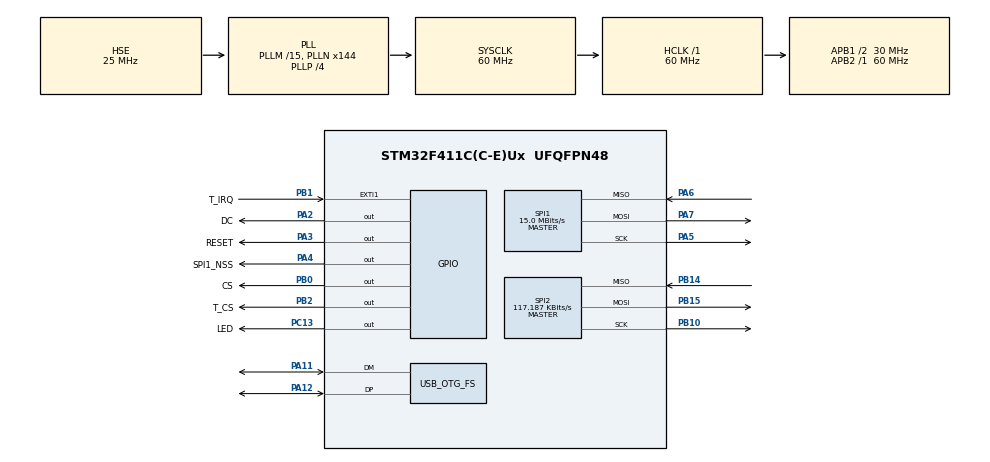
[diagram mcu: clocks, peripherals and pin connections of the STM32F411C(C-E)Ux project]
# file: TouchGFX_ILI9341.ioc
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Dma.Request0=SPI1_TX
Dma.SPI1_TX.0.Direction=DMA_MEMORY_TO_PERIPH
Dma.SPI1_TX.0.FIFOMode=DMA_FIFOMODE_ENABLE
Dma.SPI1_TX.0.FIFOThreshold=DMA_FIFO_THRESHOLD_FULL
Dma.SPI1_TX.0.Instance=DMA2_Stream2
Dma.SPI1_TX.0.MemBurst=DMA_MBURST_SINGLE
Dma.SPI1_TX.0.MemDataAlignment=DMA_MDATAALIGN_BYTE
Dma.SPI1_TX.0.MemInc=DMA_MINC_ENABLE
Dma.SPI1_TX.0.Mode=DMA_NORMAL
Dma.SPI1_TX.0.PeriphBurst=DMA_PBURST_SINGLE
Dma.SPI1_TX.0.PeriphDataAlignment=DMA_PDATAALIGN_BYTE
Dma.SPI1_TX.0.PeriphInc=DMA_PINC_DISABLE
Dma.SPI1_TX.0.Priority=DMA_PRIORITY_LOW
Mcu.Family=STM32F4
Mcu.Name=STM32F411C(C-E)Ux
Mcu.Package=UFQFPN48
NVIC.DMA2_Stream2_IRQn=true\:0\:0\:false\:false\:true\:false\:true\:true
NVIC.EXTI1_IRQn=true\:0\:0\:false\:false\:true\:true\:true\:true
NVIC.OTG_FS_IRQn=true\:0\:0\:false\:false\:true\:true\:true\:true
NVIC.PriorityGroup=NVIC_PRIORITYGROUP_4
NVIC.SPI1_IRQn=true\:0\:0\:false\:false\:true\:true\:true\:true
NVIC.SPI2_IRQn=true\:0\:0\:false\:false\:true\:true\:true\:true
NVIC.TIM1_TRG_COM_TIM11_IRQn=true\:0\:0\:true\:false\:true\:false\:true\:true
NVIC.TIM2_IRQn=true\:0\:0\:false\:false\:true\:true\:true\:true
NVIC.TimeBase=TIM1_TRG_COM_TIM11_IRQn
NVIC.TimeBaseIP=TIM11
PA11.Mode=Host_Only
PA11.Signal=USB_OTG_FS_DM
PA12.Mode=Host_Only
PA12.Signal=USB_OTG_FS_DP
PA13.Mode=Serial_Wire
PA13.Signal=SYS_JTMS-SWDIO
PA14.Mode=Serial_Wire
PA14.Signal=SYS_JTCK-SWCLK
PA2.GPIO_Label=DC
PA2.Signal=GPIO_Output
PA3.GPIO_Label=RESET
PA3.Signal=GPIO_Output
PA4.GPIO_Label=SPI1_NSS
PA4.Signal=GPIO_Output
PA5.Mode=Full_Duplex_Master
PA5.Signal=SPI1_SCK
PA6.Mode=Full_Duplex_Master
PA6.Signal=SPI1_MISO
PA7.Mode=Full_Duplex_Master
PA7.Signal=SPI1_MOSI
PB0.GPIO_Label=CS
PB0.Signal=GPIO_Output
PB1.GPIO_Label=T_IRQ
PB1.GPIO_ModeDefaultEXTI=GPIO_MODE_IT_FALLING
PB1.GPIO_PuPd=GPIO_PULLUP
PB1.Signal=GPXTI1
PB10.Mode=Full_Duplex_Master
PB10.Signal=SPI2_SCK
PB14.Mode=Full_Duplex_Master
PB14.Signal=SPI2_MISO
PB15.Mode=Full_Duplex_Master
PB15.Signal=SPI2_MOSI
PB2.GPIO_Label=T_CS
PB2.Signal=GPIO_Output
PC13-ANTI_TAMP.GPIO_Label=LED
PC13-ANTI_TAMP.GPIO_PuPd=GPIO_NOPULL
PC13-ANTI_TAMP.PinState=GPIO_PIN_SET
PC13-ANTI_TAMP.Signal=GPIO_Output
PH0\ -\ OSC_IN.Mode=HSE-External-Oscillator
PH0\ -\ OSC_IN.Signal=RCC_OSC_IN
PH1\ -\ OSC_OUT.Mode=HSE-External-Oscillator
PH1\ -\ OSC_OUT.Signal=RCC_OSC_OUT
ProjectManager.HeapSize=0x200
ProjectManager.StackSize=0x400
ProjectManager.TargetToolchain=STM32CubeIDE
RCC.48MHZClocksFreq_Value=48000000
RCC.AHBFreq_Value=60000000
RCC.APB1CLKDivider=RCC_HCLK_DIV2
RCC.APB1Freq_Value=30000000
RCC.APB1TimFreq_Value=60000000
RCC.APB2Freq_Value=60000000
RCC.APB2TimFreq_Value=60000000
RCC.CortexFreq_Value=60000000
RCC.HCLKFreq_Value=60000000
RCC.HSE_VALUE=25000000
RCC.HSI_VALUE=16000000
RCC.LSE_VALUE=32768
RCC.PLLM=15
RCC.PLLN=144
RCC.PLLP=RCC_PLLP_DIV4
RCC.PLLQ=5
RCC.SYSCLKFreq_VALUE=60000000
RCC.SYSCLKSource=RCC_SYSCLKSOURCE_PLLCLK
RCC.VCOOutputFreq_Value=240000000
SPI1.BaudRatePrescaler=SPI_BAUDRATEPRESCALER_4
SPI1.CalculateBaudRate=15.0 MBits/s
SPI1.Direction=SPI_DIRECTION_2LINES
SPI1.Mode=SPI_MODE_MASTER
SPI1.VirtualType=VM_MASTER
SPI2.BaudRatePrescaler=SPI_BAUDRATEPRESCALER_256
SPI2.CalculateBaudRate=117.187 KBits/s
SPI2.Direction=SPI_DIRECTION_2LINES
SPI2.Mode=SPI_MODE_MASTER
SPI2.VirtualType=VM_MASTER
STMicroelectronics.X-CUBE-TOUCHGFX.4.19.1.ApplicationCcGraphicsJjApplication=TouchGFXOoGenerator
STMicroelectronics.X-CUBE-TOUCHGFX.4.19.1.tgfx_buffering_strategy=Partial
STMicroelectronics.X-CUBE-TOUCHGFX.4.19.1.tgfx_custom_height=240
STMicroelectronics.X-CUBE-TOUCHGFX.4.19.1.tgfx_custom_width=320
STMicroelectronics.X-CUBE-TOUCHGFX.4.19.1_IsPackSelfContextualization=true
TIM2.Period=10000-1
TIM2.Prescaler=100-1
USB_HOST.BSP.number=1
USB_HOST.USBH_HandleTypeDef=hUsbHostFS
USB_HOST.VirtualModeFS=Hid
USB_HOST0.BSP.STBoard=false
USB_HOST0.BSP.api=Unknown
USB_HOST0.BSP.i2caddr=0
USB_HOST0.BSP.instance=PC13-ANTI_TAMP
USB_HOST0.BSP.ip=GPIO
USB_HOST0.BSP.mode=Output
USB_HOST0.BSP.name=Drive_VBUS_FS
USB_HOST0.BSP.solution=PC13-ANTI_TAMP
USB_OTG_FS.VirtualMode=Host_Only
USB_OTG_FS.phy_itface=HCD_PHY_EMBEDDED
VP_CRC_VS_CRC.Mode=CRC_Activate
VP_STMicroelectronics.X-CUBE-TOUCHGFX_VS_GraphicsJjApplication_4.19.1.Mode=GraphicsJjApplication
VP_SYS_VS_tim11.Mode=TIM11
VP_TIM2_VS_ClockSourceINT.Mode=Internal
VP_USB_HOST_VS_USB_HOST_HID_FS.Mode=HID_FS
board=custom

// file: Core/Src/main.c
/* USER CODE BEGIN Header */
/**
  ******************************************************************************
  * @file           : main.c
  * @brief          : Main program body
  ******************************************************************************
  * @attention
  *
  * Copyright (c) 2022 STMicroelectronics.
  * All rights reserved.
  *
  * This software is licensed under terms that can be found in the LICENSE file
  * in the root directory of this software component.
  * If no LICENSE file comes with this software, it is provided AS-IS.
  *
  ******************************************************************************
  */
/* USER CODE END Header */
#include "main.h"
#include "app_touchgfx.h"
#include "usb_host.h"

/* USER CODE BEGIN Includes */
#include "ili9341.h"
#include "xpt2046.h"
/* USER CODE END Includes */

 CRC_HandleTypeDef hcrc;

SPI_HandleTypeDef hspi1;
SPI_HandleTypeDef hspi2;
DMA_HandleTypeDef hdma_spi1_tx;

TIM_HandleTypeDef htim2;

void SystemClock_Config(void);
static void MX_GPIO_Init(void);
static void MX_DMA_Init(void);
static void MX_CRC_Init(void);
static void MX_SPI1_Init(void);
static void MX_SPI2_Init(void);
static void MX_TIM2_Init(void);
void MX_USB_HOST_Process(void);

int main(void)
{

  /* MCU Configuration--------------------------------------------------------*/

  /* Reset of all peripherals, Initializes the Flash interface and the Systick. */
  HAL_Init();

  /* Configure the system clock */
  SystemClock_Config();

  /* Initialize all configured peripherals */
  MX_GPIO_Init();
  MX_DMA_Init();
  MX_CRC_Init();
  MX_SPI1_Init();
  MX_SPI2_Init();
  MX_TIM2_Init();
  MX_USB_HOST_Init();
  MX_TouchGFX_Init();
  /* USER CODE BEGIN 2 */
  ILI9341_Init();
  XPT2046_Init();
  HAL_TIM_Base_Start_IT(&htim2);
  /* USER CODE END 2 */

  /* Infinite loop */
  while (1)
  {
    MX_USB_HOST_Process();

  MX_TouchGFX_Process();
  }
}

void SystemClock_Config(void)
{
  RCC_OscInitTypeDef RCC_OscInitStruct = {0};
  RCC_ClkInitTypeDef RCC_ClkInitStruct = {0};

  /** Configure the main internal regulator output voltage
  */
  __HAL_RCC_PWR_CLK_ENABLE();
  __HAL_PWR_VOLTAGESCALING_CONFIG(PWR_REGULATOR_VOLTAGE_SCALE1);

  /** Initializes the RCC Oscillators according to the specified parameters
  * in the RCC_OscInitTypeDef structure.
  */
  RCC_OscInitStruct.OscillatorType = RCC_OSCILLATORTYPE_HSE;
  RCC_OscInitStruct.HSEState = RCC_HSE_ON;
  RCC_OscInitStruct.PLL.PLLState = RCC_PLL_ON;
  RCC_OscInitStruct.PLL.PLLSource = RCC_PLLSOURCE_HSE;
  RCC_OscInitStruct.PLL.PLLM = 15;
  RCC_OscInitStruct.PLL.PLLN = 144;
  RCC_OscInitStruct.PLL.PLLP = RCC_PLLP_DIV4;
  RCC_OscInitStruct.PLL.PLLQ = 5;
  if (HAL_RCC_OscConfig(&RCC_OscInitStruct) != HAL_OK)
  {
    Error_Handler();
  }

  /** Initializes the CPU, AHB and APB buses clocks
  */
  RCC_ClkInitStruct.ClockType = RCC_CLOCKTYPE_HCLK|RCC_CLOCKTYPE_SYSCLK
                              |RCC_CLOCKTYPE_PCLK1|RCC_CLOCKTYPE_PCLK2;
  RCC_ClkInitStruct.SYSCLKSource = RCC_SYSCLKSOURCE_PLLCLK;
  RCC_ClkInitStruct.AHBCLKDivider = RCC_SYSCLK_DIV1;
  RCC_ClkInitStruct.APB1CLKDivider = RCC_HCLK_DIV2;
  RCC_ClkInitStruct.APB2CLKDivider = RCC_HCLK_DIV1;

  if (HAL_RCC_ClockConfig(&RCC_ClkInitStruct, FLASH_LATENCY_1) != HAL_OK)
  {
    Error_Handler();
  }
}

static void MX_CRC_Init(void)
{

  hcrc.Instance = CRC;
  if (HAL_CRC_Init(&hcrc) != HAL_OK)
  {
    Error_Handler();
  }

}

static void MX_SPI1_Init(void)
{

  /* SPI1 parameter configuration*/
  hspi1.Instance = SPI1;
  hspi1.Init.Mode = SPI_MODE_MASTER;
  hspi1.Init.Direction = SPI_DIRECTION_2LINES;
  hspi1.Init.DataSize = SPI_DATASIZE_8BIT;
  hspi1.Init.CLKPolarity = SPI_POLARITY_LOW;
  hspi1.Init.CLKPhase = SPI_PHASE_1EDGE;
  hspi1.Init.NSS = SPI_NSS_SOFT;
  hspi1.Init.BaudRatePrescaler = SPI_BAUDRATEPRESCALER_4;
  hspi1.Init.FirstBit = SPI_FIRSTBIT_MSB;
  hspi1.Init.TIMode = SPI_TIMODE_DISABLE;
  hspi1.Init.CRCCalculation = SPI_CRCCALCULATION_DISABLE;
  hspi1.Init.CRCPolynomial = 10;
  if (HAL_SPI_Init(&hspi1) != HAL_OK)
  {
    Error_Handler();
  }

}

static void MX_SPI2_Init(void)
{

  /* SPI2 parameter configuration*/
  hspi2.Instance = SPI2;
  hspi2.Init.Mode = SPI_MODE_MASTER;
  hspi2.Init.Direction = SPI_DIRECTION_2LINES;
  hspi2.Init.DataSize = SPI_DATASIZE_8BIT;
  hspi2.Init.CLKPolarity = SPI_POLARITY_LOW;
  hspi2.Init.CLKPhase = SPI_PHASE_1EDGE;
  hspi2.Init.NSS = SPI_NSS_SOFT;
  hspi2.Init.BaudRatePrescaler = SPI_BAUDRATEPRESCALER_256;
  hspi2.Init.FirstBit = SPI_FIRSTBIT_MSB;
  hspi2.Init.TIMode = SPI_TIMODE_DISABLE;
  hspi2.Init.CRCCalculation = SPI_CRCCALCULATION_DISABLE;
  hspi2.Init.CRCPolynomial = 10;
  if (HAL_SPI_Init(&hspi2) != HAL_OK)
  {
    Error_Handler();
  }

}

static void MX_TIM2_Init(void)
{

  TIM_ClockConfigTypeDef sClockSourceConfig = {0};
  TIM_MasterConfigTypeDef sMasterConfig = {0};

  htim2.Instance = TIM2;
  htim2.Init.Prescaler = 100-1;
  htim2.Init.CounterMode = TIM_COUNTERMODE_UP;
  htim2.Init.Period = 10000-1;
  htim2.Init.ClockDivision = TIM_CLOCKDIVISION_DIV1;
  htim2.Init.AutoReloadPreload = TIM_AUTORELOAD_PRELOAD_DISABLE;
  if (HAL_TIM_Base_Init(&htim2) != HAL_OK)
  {
    Error_Handler();
  }
  sClockSourceConfig.ClockSource = TIM_CLOCKSOURCE_INTERNAL;
  if (HAL_TIM_ConfigClockSource(&htim2, &sClockSourceConfig) != HAL_OK)
  {
    Error_Handler();
  }
  sMasterConfig.MasterOutputTrigger = TIM_TRGO_RESET;
  sMasterConfig.MasterSlaveMode = TIM_MASTERSLAVEMODE_DISABLE;
  if (HAL_TIMEx_MasterConfigSynchronization(&htim2, &sMasterConfig) != HAL_OK)
  {
    Error_Handler();
  }

}

static void MX_DMA_Init(void)
{

  /* DMA controller clock enable */
  __HAL_RCC_DMA2_CLK_ENABLE();

  /* DMA interrupt init */
  /* DMA2_Stream2_IRQn interrupt configuration */
  HAL_NVIC_SetPriority(DMA2_Stream2_IRQn, 0, 0);
  HAL_NVIC_EnableIRQ(DMA2_Stream2_IRQn);

}

static void MX_GPIO_Init(void)
{
  GPIO_InitTypeDef GPIO_InitStruct = {0};

  /* GPIO Ports Clock Enable */
  __HAL_RCC_GPIOC_CLK_ENABLE();
  __HAL_RCC_GPIOH_CLK_ENABLE();
  __HAL_RCC_GPIOA_CLK_ENABLE();
  __HAL_RCC_GPIOB_CLK_ENABLE();

  /*Configure GPIO pin Output Level */
  HAL_GPIO_WritePin(LED_GPIO_Port, LED_Pin, GPIO_PIN_SET);

  /*Configure GPIO pin Output Level */
  HAL_GPIO_WritePin(GPIOA, DC_Pin|RESET_Pin|SPI1_NSS_Pin, GPIO_PIN_RESET);

  /*Configure GPIO pin Output Level */
  HAL_GPIO_WritePin(GPIOB, CS_Pin|T_CS_Pin, GPIO_PIN_RESET);

  /*Configure GPIO pin : LED_Pin */
  GPIO_InitStruct.Pin = LED_Pin;
  GPIO_InitStruct.Mode = GPIO_MODE_OUTPUT_PP;
  GPIO_InitStruct.Pull = GPIO_NOPULL;
  GPIO_InitStruct.Speed = GPIO_SPEED_FREQ_LOW;
  HAL_GPIO_Init(LED_GPIO_Port, &GPIO_InitStruct);

  /*Configure GPIO pins : DC_Pin RESET_Pin SPI1_NSS_Pin */
  GPIO_InitStruct.Pin = DC_Pin|RESET_Pin|SPI1_NSS_Pin;
  GPIO_InitStruct.Mode = GPIO_MODE_OUTPUT_PP;
  GPIO_InitStruct.Pull = GPIO_NOPULL;
  GPIO_InitStruct.Speed = GPIO_SPEED_FREQ_LOW;
  HAL_GPIO_Init(GPIOA, &GPIO_InitStruct);

  /*Configure GPIO pins : CS_Pin T_CS_Pin */
  GPIO_InitStruct.Pin = CS_Pin|T_CS_Pin;
  GPIO_InitStruct.Mode = GPIO_MODE_OUTPUT_PP;
  GPIO_InitStruct.Pull = GPIO_NOPULL;
  GPIO_InitStruct.Speed = GPIO_SPEED_FREQ_LOW;
  HAL_GPIO_Init(GPIOB, &GPIO_InitStruct);

  /*Configure GPIO pin : T_IRQ_Pin */
  GPIO_InitStruct.Pin = T_IRQ_Pin;
  GPIO_InitStruct.Mode = GPIO_MODE_IT_FALLING;
  GPIO_InitStruct.Pull = GPIO_PULLUP;
  HAL_GPIO_Init(T_IRQ_GPIO_Port, &GPIO_InitStruct);

  /* EXTI interrupt init*/
  HAL_NVIC_SetPriority(EXTI1_IRQn, 0, 0);
  HAL_NVIC_EnableIRQ(EXTI1_IRQn);

}

void HAL_TIM_PeriodElapsedCallback(TIM_HandleTypeDef *htim)
{
  /* USER CODE BEGIN Callback 0 */
	extern void touchgfxSignalVSync(void);
		if (htim->Instance == TIM2) {
		touchgfxSignalVSync();
	}
  /* USER CODE END Callback 0 */
  if (htim->Instance == TIM11) {
    HAL_IncTick();
  }
}

void Error_Handler(void)
{
  __disable_irq();
  while (1)
  {
  }
}
